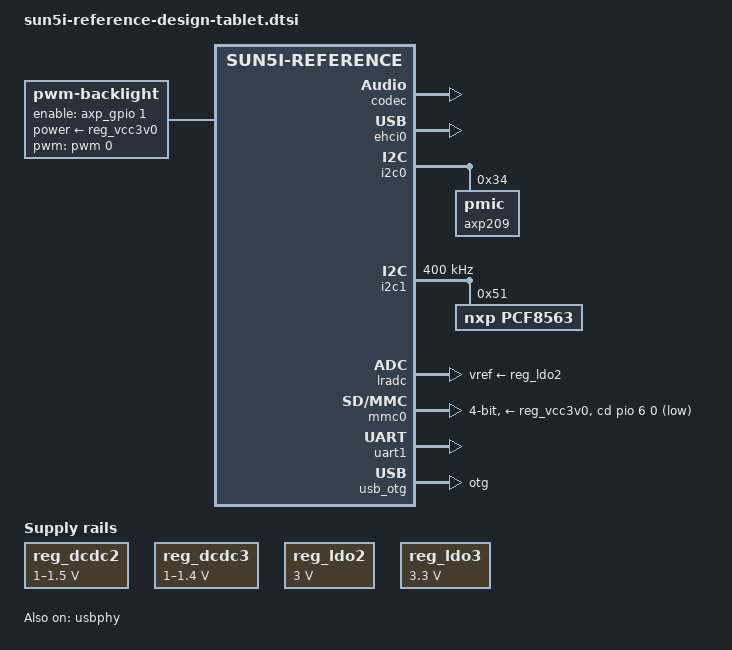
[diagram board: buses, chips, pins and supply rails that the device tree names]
#include "sunxi-reference-design-tablet.dtsi"
#include <dt-bindings/interrupt-controller/irq.h>
#include <dt-bindings/pwm/pwm.h>
/ {
	aliases {
		serial0 = &uart1;
	};
	backlight: backlight {
		compatible = "pwm-backlight";
		pwms = <&pwm 0 50000 PWM_POLARITY_INVERTED>;
		brightness-levels = <0 10 20 30 40 50 60 70 80 90 100>;
		default-brightness-level = <8>;
		enable-gpios = <&axp_gpio 1 GPIO_ACTIVE_HIGH>;  
		power-supply = <&reg_vcc3v0>;
	};
	chosen {
		stdout-path = "serial0:115200n8";
	};
};
&codec {
	allwinner,pa-gpios = <&pio 6 10 GPIO_ACTIVE_HIGH>;  
	status = "okay";
};
&cpu0 {
	cpu-supply = <&reg_dcdc2>;
};
&ehci0 {
	status = "okay";
};
&i2c0 {
	axp209: pmic@34 {
		reg = <0x34>;
		interrupts = <0>;
	};
};
&i2c1 {
	clock-frequency = <400000>;
	touchscreen: touchscreen@40 {
		reg = <0x40>;
		interrupt-parent = <&pio>;
		interrupts = <6 11 IRQ_TYPE_EDGE_FALLING>;  
		power-gpios = <&pio 1 3 GPIO_ACTIVE_HIGH>;  
		status = "disabled";
	};
	pcf8563: rtc@51 {
		compatible = "nxp,pcf8563";
		reg = <0x51>;
	};
};
#include "axp209.dtsi"
&ac_power_supply {
	status = "okay";
};
&battery_power_supply {
	status = "okay";
};
&lradc {
	vref-supply = <&reg_ldo2>;
};
&mmc0 {
	pinctrl-names = "default";
	pinctrl-0 = <&mmc0_pins>;
	vmmc-supply = <&reg_vcc3v0>;
	bus-width = <4>;
	cd-gpios = <&pio 6 0 GPIO_ACTIVE_LOW>;  
	status = "okay";
};
&otg_sram {
	status = "okay";
};
&reg_dcdc2 {
	regulator-always-on;
	regulator-min-microvolt = <1000000>;
	regulator-max-microvolt = <1500000>;
	regulator-name = "vdd-cpu";
};
&reg_dcdc3 {
	regulator-always-on;
	regulator-min-microvolt = <1000000>;
	regulator-max-microvolt = <1400000>;
	regulator-name = "vdd-int-pll";
};
&reg_ldo1 {
	regulator-name = "vdd-rtc";
};
&reg_ldo2 {
	regulator-always-on;
	regulator-min-microvolt = <3000000>;
	regulator-max-microvolt = <3000000>;
	regulator-name = "avcc";
};
&reg_ldo3 {
	regulator-min-microvolt = <3300000>;
	regulator-max-microvolt = <3300000>;
	regulator-name = "vcc-wifi";
};
&reg_usb0_vbus {
	gpio = <&pio 6 12 GPIO_ACTIVE_HIGH>;  
	status = "okay";
};
&uart1 {
	pinctrl-names = "default";
	pinctrl-0 = <&uart1_pg_pins>;
	status = "okay";
};
&usb_otg {
	dr_mode = "otg";
	status = "okay";
};
&usb_power_supply {
	status = "okay";
};
&usbphy {
	usb0_id_det-gpios = <&pio 6 2 (GPIO_ACTIVE_HIGH | GPIO_PULL_UP)>;  
	usb0_vbus_det-gpios = <&pio 6 1 (GPIO_ACTIVE_HIGH | GPIO_PULL_DOWN)>;  
	usb0_vbus_power-supply = <&usb_power_supply>;
	usb0_vbus-supply = <&reg_usb0_vbus>;
	usb1_vbus-supply = <&reg_ldo3>;
	status = "okay";
};
